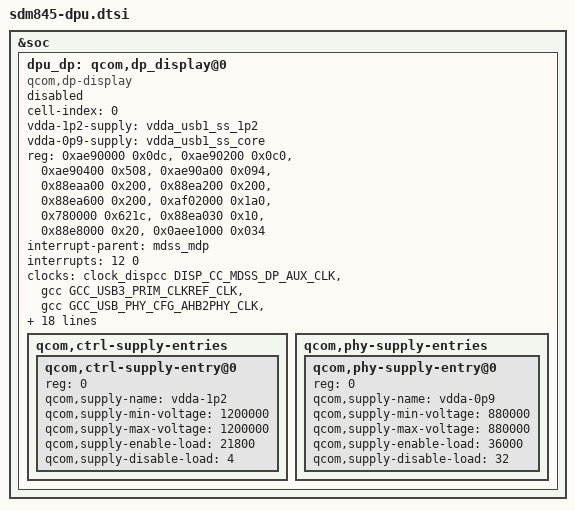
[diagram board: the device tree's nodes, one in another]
/* Copyright (c) 2016-2018, The Linux Foundation. All rights reserved.
 *
 * This program is free software; you can redistribute it and/or modify
 * it under the terms of the GNU General Public License version 2 and
 * only version 2 as published by the Free Software Foundation.
 *
 * This program is distributed in the hope that it will be useful,
 * but WITHOUT ANY WARRANTY; without even the implied warranty of
 * MERCHANTABILITY or FITNESS FOR A PARTICULAR PURPOSE.  See the
 * GNU General Public License for more details.
 */
#include <dt-bindings/clock/mdss-10nm-pll-clk.h>

&soc {
	dpu_dp: qcom,dp_display@0{
		status = "disabled";
		cell-index = <0>;
		compatible = "qcom,dp-display";
		/*gdsc-supply = <&mdss_core_gdsc>;*/
		vdda-1p2-supply = <&vdda_usb1_ss_1p2>;
		vdda-0p9-supply = <&vdda_usb1_ss_core>;

		reg =	<0xae90000 0x0dc>,
			<0xae90200 0x0c0>,
			<0xae90400 0x508>,
			<0xae90a00 0x094>,
			<0x88eaa00 0x200>,
			<0x88ea200 0x200>,
			<0x88ea600 0x200>,
			<0xaf02000 0x1a0>,
			<0x780000 0x621c>,
			<0x88ea030 0x10>,
			<0x88e8000 0x20>,
			<0x0aee1000 0x034>;
		/* dp_ctrl: dp_ahb, dp_aux, dp_link, dp_p0 */
		reg-names = "dp_ahb", "dp_aux", "dp_link",
			"dp_p0", "dp_phy", "dp_ln_tx0", "dp_ln_tx1",
			"dp_mmss_cc", "qfprom_physical", "dp_pll",
			"usb3_dp_com", "hdcp_physical";

		interrupt-parent = <&mdss_mdp>;
		interrupts = <12 0>;

		clocks =  <&clock_dispcc DISP_CC_MDSS_DP_AUX_CLK>,
			 /*<&clock_rpmh RPMH_CXO_CLK>,*/
			 <&gcc GCC_USB3_PRIM_CLKREF_CLK>,
			 <&gcc GCC_USB_PHY_CFG_AHB2PHY_CLK>,
			 <&gcc GCC_USB3_PRIM_PHY_PIPE_CLK>,
			 <&clock_dispcc DISP_CC_MDSS_DP_LINK_CLK>,
			 <&clock_dispcc DISP_CC_MDSS_DP_LINK_INTF_CLK>,
			 <&clock_dispcc DISP_CC_MDSS_DP_PIXEL_CLK>,
			 <&clock_dispcc DISP_CC_MDSS_DP_CRYPTO_CLK>,
			 <&clock_dispcc DISP_CC_MDSS_DP_PIXEL_CLK_SRC>,
			 <&mdss_dp_pll DP_VCO_DIVIDED_CLK_SRC_MUX>;
		clock-names = "core_aux_clk", "core_usb_ref_clk_src",
			"core_usb_ref_clk", "core_usb_cfg_ahb_clk",
			"core_usb_pipe_clk", "ctrl_link_clk",
			"ctrl_link_iface_clk", "ctrl_pixel_clk",
			"crypto_clk", "pixel_clk_rcg", "pixel_parent";

		qcom,aux-cfg0-settings = [20 00];
		qcom,aux-cfg1-settings = [24 13 23 1d];
		qcom,aux-cfg2-settings = [28 24];
		qcom,aux-cfg3-settings = [2c 00];
		qcom,aux-cfg4-settings = [30 0a];
		qcom,aux-cfg5-settings = [34 26];
		qcom,aux-cfg6-settings = [38 0a];
		qcom,aux-cfg7-settings = [3c 03];
		qcom,aux-cfg8-settings = [40 bb];
		qcom,aux-cfg9-settings = [44 03];

		qcom,max-pclk-frequency-khz = <675000>;

		qcom,ctrl-supply-entries {
			#address-cells = <1>;
			#size-cells = <0>;

			qcom,ctrl-supply-entry@0 {
				reg = <0>;
				qcom,supply-name = "vdda-1p2";
				qcom,supply-min-voltage = <1200000>;
				qcom,supply-max-voltage = <1200000>;
				qcom,supply-enable-load = <21800>;
				qcom,supply-disable-load = <4>;
			};
		};

		qcom,phy-supply-entries {
			#address-cells = <1>;
			#size-cells = <0>;

			qcom,phy-supply-entry@0 {
				reg = <0>;
				qcom,supply-name = "vdda-0p9";
				qcom,supply-min-voltage = <880000>;
				qcom,supply-max-voltage = <880000>;
				qcom,supply-enable-load = <36000>;
				qcom,supply-disable-load = <32>;
			};
		};
	};
};
